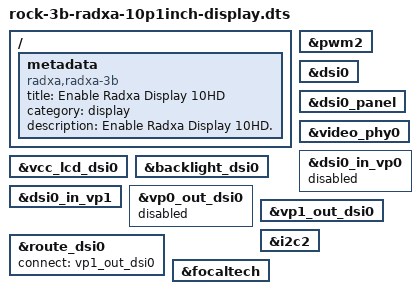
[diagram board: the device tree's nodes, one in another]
/dts-v1/;
/plugin/;

/ {
	metadata {
		title = "Enable Radxa Display 10HD";
		compatible = "radxa,radxa-3b";
		category = "display";
		description = "Enable Radxa Display 10HD.";
	};

	fragment@0 {
		target = <&vcc_lcd_dsi0>;

		__overlay__ {
			status = "okay";
		};
	};

	fragment@1 {
		target = <&backlight_dsi0>;

		__overlay__ {
			status = "okay";
		};
	};

	fragment@2 {
		target = <&pwm2>;

		__overlay__ {
			status = "okay";
		};
	};

	fragment@3 {
		target = <&dsi0>;

		__overlay__ {
			status = "okay";
		};
	};

	fragment@4 {
		target = <&dsi0_panel>;

		__overlay__ {
			status = "okay";
		};
	};

	fragment@5 {
		target = <&video_phy0>;

		__overlay__ {
			status = "okay";
		};
	};

	fragment@6 {
		target = <&dsi0_in_vp0>;

		__overlay__ {
			status = "disabled";
		};
	};

	fragment@7 {
		target = <&dsi0_in_vp1>;

		__overlay__ {
			status = "okay";
		};
	};

	fragment@8 {
		target = <&vp0_out_dsi0>;

		__overlay__ {
			status = "disabled";
		};
	};

	fragment@9 {
		target = <&vp1_out_dsi0>;

		__overlay__ {
			status = "okay";
		};
	};

	fragment@10 {
		target = <&route_dsi0>;

		__overlay__ {
			status = "okay";
			connect = <&vp1_out_dsi0>;
		};
	};

	fragment@11 {
		target = <&i2c2>;

		__overlay__ {
			status = "okay";
		};
	};

	fragment@12 {
		target = <&focaltech>;

		__overlay__ {
			status = "okay";
		};
	};
};
